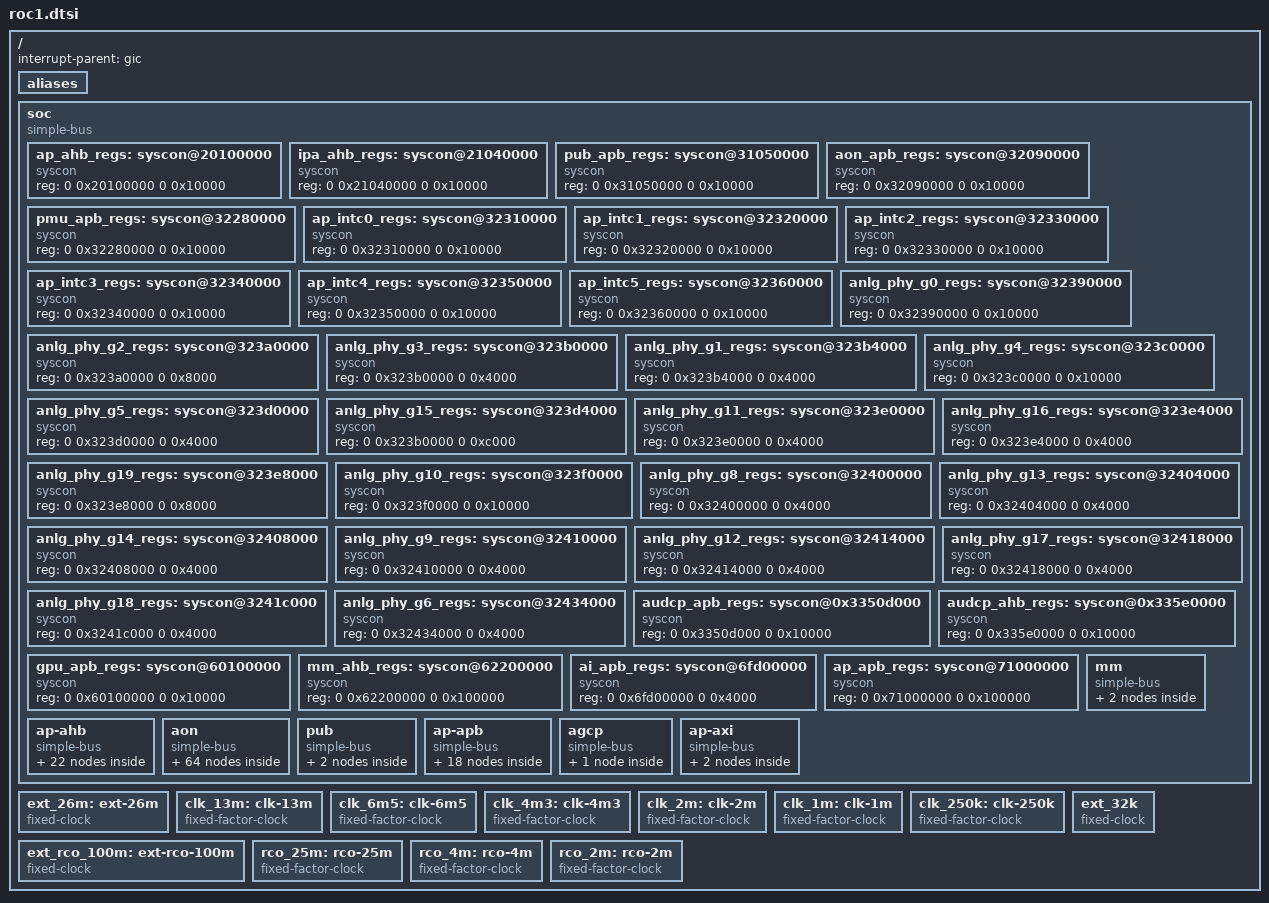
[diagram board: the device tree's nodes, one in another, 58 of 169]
/*
 * Spreadtrum Roc1 platform DTS file
 *
 * Copyright (C) 2018, Spreadtrum Communications Inc.
 *
 * This file is licensed under a dual GPLv2 or X11 license.
 */

#include <dt-bindings/soc/sprd,roc1-regs.h>
#include <dt-bindings/soc/sprd,roc1-mask.h>
#include <dt-bindings/clock/sprd,roc1-clk.h>
#include <dt-bindings/interrupt-controller/arm-gic.h>
#include <dt-bindings/debug/busmonitor/busmonitor.h>
#include <dt-bindings/debug/dmc_mpu/roc1_dmc_mpu.h>

/ {
	interrupt-parent = <&gic>;
	#address-cells = <2>;
	#size-cells = <2>;

	aliases {
		i2c0 = &i2c0;
		i2c1 = &i2c1;
		i2c2 = &i2c2;
		i2c3 = &i2c3;
		i2c4 = &i2c4;
		i2c5 = &i2c5;
		i2c6 = &i2c6;
		spi0 = &spi0;
		spi1 = &spi1;
		spi2 = &spi2;
		spi3 = &spi3;
	};

	soc: soc {
		compatible = "simple-bus";
		#address-cells = <2>;
		#size-cells = <2>;
		ranges;

		ap_ahb_regs: syscon@20100000 {
			compatible = "syscon";
			#syscon-cells = <2>;
			reg = <0 0x20100000 0 0x10000>;
		};

		ipa_ahb_regs: syscon@21040000 {
			compatible = "syscon";
			#syscon-cells = <2>;
			reg = <0 0x21040000 0 0x10000>;
		};

		pub_apb_regs: syscon@31050000 {
			compatible = "syscon";
			#syscon-cells = <2>;
			reg = <0 0x31050000 0 0x10000>;
		};

		aon_apb_regs: syscon@32090000 {
			compatible = "syscon";
			#syscon-cells = <2>;
			reg = <0 0x32090000 0 0x10000>;
		};

		pmu_apb_regs: syscon@32280000 {
			compatible = "syscon";
			#syscon-cells = <2>;
			reg = <0 0x32280000 0 0x10000>;
		};

		ap_intc0_regs: syscon@32310000 {
			compatible = "syscon";
			#syscon-cells = <2>;
			reg = <0 0x32310000 0 0x10000>;
		};

		ap_intc1_regs: syscon@32320000 {
			compatible = "syscon";
			#syscon-cells = <2>;
			reg = <0 0x32320000 0 0x10000>;
		};

		ap_intc2_regs: syscon@32330000 {
			compatible = "syscon";
			#syscon-cells = <2>;
			reg = <0 0x32330000 0 0x10000>;
		};

		ap_intc3_regs: syscon@32340000 {
			compatible = "syscon";
			#syscon-cells = <2>;
			reg = <0 0x32340000 0 0x10000>;
		};

		ap_intc4_regs: syscon@32350000 {
			compatible = "syscon";
			#syscon-cells = <2>;
			reg = <0 0x32350000 0 0x10000>;
		};

		ap_intc5_regs: syscon@32360000 {
			compatible = "syscon";
			#syscon-cells = <2>;
			reg = <0 0x32360000 0 0x10000>;
		};

		anlg_phy_g0_regs: syscon@32390000 {
			compatible = "syscon";
			#syscon-cells = <2>;
			reg = <0 0x32390000 0 0x10000>;
		};

		anlg_phy_g2_regs: syscon@323a0000 {
			compatible = "syscon";
			#syscon-cells = <2>;
			reg = <0 0x323a0000 0 0x8000>;
		};

		anlg_phy_g3_regs: syscon@323b0000 {
			compatible = "syscon";
			#syscon-cells = <2>;
			reg = <0 0x323b0000 0 0x4000>;
		};

		anlg_phy_g1_regs: syscon@323b4000 {
			compatible = "syscon";
			#syscon-cells = <2>;
			reg = <0 0x323b4000 0 0x4000>;
		};

		anlg_phy_g4_regs: syscon@323c0000 {
			compatible = "syscon";
			#syscon-cells = <2>;
			reg = <0 0x323c0000 0 0x10000>;
		};

		anlg_phy_g5_regs: syscon@323d0000 {
			compatible = "syscon";
			#syscon-cells = <2>;
			reg = <0 0x323d0000 0 0x4000>;
		};

		anlg_phy_g15_regs: syscon@323d4000 {
			compatible = "syscon";
			#syscon-cells = <2>;
			reg = <0 0x323b0000 0 0xc000>;
		};

		anlg_phy_g11_regs: syscon@323e0000 {
			compatible = "syscon";
			#syscon-cells = <2>;
			reg = <0 0x323e0000 0 0x4000>;
		};

		anlg_phy_g16_regs: syscon@323e4000 {
			compatible = "syscon";
			#syscon-cells = <2>;
			reg = <0 0x323e4000 0 0x4000>;
		};

		anlg_phy_g19_regs: syscon@323e8000 {
			compatible = "syscon";
			#syscon-cells = <2>;
			reg = <0 0x323e8000 0 0x8000>;
		};

		anlg_phy_g10_regs: syscon@323f0000 {
			compatible = "syscon";
			#syscon-cells = <2>;
			reg = <0 0x323f0000 0 0x10000>;
		};

		anlg_phy_g8_regs: syscon@32400000 {
			compatible = "syscon";
			#syscon-cells = <2>;
			reg = <0 0x32400000 0 0x4000>;
		};

		anlg_phy_g13_regs: syscon@32404000 {
			compatible = "syscon";
			#syscon-cells = <2>;
			reg = <0 0x32404000 0 0x4000>;
		};

		anlg_phy_g14_regs: syscon@32408000 {
			compatible = "syscon";
			#syscon-cells = <2>;
			reg = <0 0x32408000 0 0x4000>;
		};

		anlg_phy_g9_regs: syscon@32410000 {
			compatible = "syscon";
			#syscon-cells = <2>;
			reg = <0 0x32410000 0 0x4000>;
		};

		anlg_phy_g12_regs: syscon@32414000 {
			compatible = "syscon";
			#syscon-cells = <2>;
			reg = <0 0x32414000 0 0x4000>;
		};

		anlg_phy_g17_regs: syscon@32418000 {
			compatible = "syscon";
			#syscon-cells = <2>;
			reg = <0 0x32418000 0 0x4000>;
		};

		anlg_phy_g18_regs: syscon@3241c000 {
			compatible = "syscon";
			#syscon-cells = <2>;
			reg = <0 0x3241c000 0 0x4000>;
		};

		anlg_phy_g6_regs: syscon@32434000 {
			compatible = "syscon";
			#syscon-cells = <2>;
			reg = <0 0x32434000 0 0x4000>;
		};

		audcp_apb_regs: syscon@0x3350d000 {
			compatible = "syscon";
			#syscon-cells = <2>;
			reg = <0 0x3350d000 0 0x10000>;
		};

		audcp_ahb_regs: syscon@0x335e0000 {
			compatible = "syscon";
			#syscon-cells = <2>;
			reg = <0 0x335e0000 0 0x10000>;
		};

		gpu_apb_regs: syscon@60100000 {
			compatible = "syscon";
			#syscon-cells = <2>;
			reg = <0 0x60100000 0 0x10000>;
		};

		mm_ahb_regs: syscon@62200000 {
			compatible = "syscon";
			#syscon-cells = <2>;
			reg = <0 0x62200000 0 0x100000>;
		};

		ai_apb_regs: syscon@6fd00000 {
			compatible = "syscon";
			#syscon-cells = <2>;
			reg = <0 0x6fd00000 0 0x4000>;
		};

		ap_apb_regs: syscon@71000000 {
			compatible = "syscon";
			#syscon-cells = <2>;
			reg = <0 0x71000000 0 0x100000>;
		};

		mm {
			compatible = "simple-bus";
			#address-cells = <2>;
			#size-cells = <2>;
			ranges;

			gpu: gpu@60000000 {
				compatible = "sprd,rogue";
				reg = <0x0 0x60000000 0x0 0x100000>;
				interrupts = <GIC_SPI 60 IRQ_TYPE_LEVEL_HIGH>;
			};

			jpg: jpg-codec@62700000{
				compatible = "sprd,roc1-jpg";
				reg = <0 0x62700000 0 0xc000>;
				interrupts = <GIC_SPI 42 IRQ_TYPE_LEVEL_HIGH>;

				syscons = <&mm_ahb_regs REG_MM_AHB_AHB_RST
						MASK_MM_AHB_JPG_SOFT_RST>,
					<&aon_apb_regs
						REG_AON_APB_APB_EB0
						MASK_AON_APB_MM_EB>;
				syscon-names = "reset",
					"aon_apb_eb";
				status = "disabled";
			};
		};

		ap-ahb {
			compatible = "simple-bus";
			#address-cells = <2>;
			#size-cells = <2>;
			ranges;

			ap_dma: dma-controller@20000000 {
				compatible = "sprd,roc1-dma";
				reg = <0 0x20000000 0 0x4000>;
				interrupts = <GIC_SPI 24 IRQ_TYPE_LEVEL_HIGH>;
				#dma-cells = <1>;
				#dma-channels = <28>;
				clock-names = "enable";
				clocks = <&apahb_gate CLK_DMA_PUB_EB>;
			};

			hsphy: hsphy@20100000 {
				compatible = "sprd,roc1-phy";
				sprd,syscon-enable = <&aon_apb_regs>;
				sprd,syscon-anag3 = <&anlg_phy_g3_regs>;
				sprd,vdd-voltage = <3300000>;
				#phy-cells = <0>;
			};

			dpu: dpu@20300000 {
				compatible = "sprd,display-processor";
				reg = <0 0x20300000 0 0x1000>;
				interrupts = <GIC_SPI 27 IRQ_TYPE_LEVEL_HIGH>;
				status = "disabled";

				dma-coherent;

				sprd,ip = "dpu-r3p0";
				/* sprd,soc = "roc1"; */

				//sprd,syscon-aon-apb = <&aon_apb_controller>;

				dpu_port: port {
					dpu_out: endpoint {
						remote-endpoint = <&dsi_in>;
					};
				};
			};

			gsp_core0: gsp@20300000 {
				compatible = "sprd,gsp-core";
				reg = <0 0x20300000 0 0x2000>;
				core-id = <0>;
				kcfg-num = <16>;
				interrupts = <GIC_SPI 26 IRQ_TYPE_LEVEL_HIGH>;
				iommus = <&iommu_dispc>;
			};

			iommu_dispc: iommu@20300000 {
				compatible = "sprd,iommuexroc1-dispc";
				reg = <0 0x20300000 0 0x800>,
				      <0 0x20300800 0 0x80>;
				iova-base = <0x30000000>;
				iova-size = <0x10000000>;
				reg_name = "mmu_interrupt_reg","mmu_reg";
				status = "disabled";
				#iommu-cells = <0>;
			};

			iommu_ai: iommu@6fe00000 {
				compatible = "sprd,iommuexroc1-ai";
				reg = <0 0x6fe00000 0 0x800>,
				      <0 0x6fd08004 0 0x80>;
				iova-base = <0x30000000>;
				iova-size = <0x20000000>;
				reg_name = "mmu_interrupt_reg","mmu_reg";
				status = "disabled";
				#iommu-cells = <0>;
			};

			dsi: dsi@20400000 {
				compatible = "sprd,dsi-host";
				reg = <0 0x20400000 0 0x1000>;
				interrupts = <GIC_SPI 30 IRQ_TYPE_LEVEL_HIGH>,
					<GIC_SPI 31 IRQ_TYPE_LEVEL_HIGH>;
				status = "disabled";

				sprd,ip = "sprd,dsi-ctrl", "r3p0";
				sprd,soc = "roc1";

				//sprd,syscon-aon-apb = <&aon_apb_controller>;

				ports {
					#address-cells = <1>;
					#size-cells = <0>;

					port@0 {
						reg = <0>;
						dsi_out: endpoint {
							remote-endpoint = <&dphy_in>;
						};
					};

					port@1 {
						reg = <1>;
						dsi_in: endpoint@1 {
							remote-endpoint = <&dpu_out>;
						};
					};
				};
			};

			dphy: dphy {
				compatible = "sprd,dsi-phy";
				#address-cells = <1>;
				#size-cells = <0>;
				reg = <0 0x20400000 0 0x1000>;
				status = "disabled";

				sprd,ip = "sprd,megacores-sharkl5";
				sprd,soc = "roc1";

				//sprd,syscon-aon-apb = <&aon_apb_controller>;

				/* output port */
				port@0 {
					reg = <0>;
					dphy_out: endpoint {
						remote-endpoint = <&panel_in>;
					};
				};

				/* input port*/
				port@1 {
					reg = <1>;
					dphy_in: endpoint {
						remote-endpoint = <&dsi_out>;
					};
				};
			};

			vsp: video-codec@20500000{
				compatible = "sprd,roc1-vsp";
				reg = <0 0x20500000 0 0xc000>;
				interrupts = <GIC_SPI 34 IRQ_TYPE_LEVEL_HIGH>;
				syscons = <&ap_ahb_regs REG_AP_AHB_AHB_RST
					(MASK_AP_AHB_VSP_SOFT_RST |
					MASK_AP_AHB_VSP_GLOBAL_SOFT_RST)>,
					<&pmu_apb_regs
					REG_PMU_APB_PD_AP_VSP_CFG
					MASK_PMU_APB_PD_AP_VSP_FORCE_SHUTDOWN>,
					<&pmu_apb_regs
					REG_PMU_APB_PD_AP_VSP_CFG
					MASK_PMU_APB_PD_AP_VSP_AUTO_SHUTDOWN_EN>
					,
					<&pmu_apb_regs
					REG_PMU_APB_PWR_STATUS0_DBG
					MASK_PMU_APB_PD_AP_VSP_STATE>,
					<&aon_apb_regs
					REG_AON_APB_APB_EB1
					MASK_AON_APB_AP_SYST_EB>;
				syscon-names = "reset",
					"pmu_vsp_force_shutdown",
					"pmu_vsp_auto_shutdown",
					"pmu_pwr_status",
					"vsp_domain_eb";
				status = "disabled";
			};

			pcie0: pcie@20c00000 {
				compatible = "sprd,pcie", "snps,dw-pcie";
				reg = <0x0 0x20c00000 0x0 0x100000>,
				      <0x3 0xffffe000 0x0 0x2000>;
				reg-names = "dbi", "config";
				#address-cells = <3>;
				#size-cells = <2>;
				device_type = "pci";
				ranges = <0x01000000 0x0 0x00000000 0x3 0xfffee000 0x0 0x00010000
					  0x03000000 0x0 0x10000000 0x3 0xf8000000 0x0 0x07fee000>;
				interrupts = <GIC_SPI 148 IRQ_TYPE_LEVEL_HIGH>;
				bus-range = <0 15>;
				num-lanes = <1>;
				num-vectors = <256>;
				num-viewport = <8>;
				status = "okay";
			};

			pcie1: pcie@20d00000 {
				compatible = "sprd,pcie", "snps,dw-pcie";
				reg = <0x0 0x20d00000 0x0 0x100000>,
				      <0x3 0xf7f00000 0x0 0x100000>;
				reg-names = "dbi", "config";
				#address-cells = <3>;
				#size-cells = <2>;
				device_type = "pci";
				ranges = <0x01000000 0x0 0x00000000 0x3 0xf7ef0000 0x0 0x00010000
					  0x03000000 0x0 0x10000000 0x2 0x80000000 0x1 0x77ef0000>;
				interrupts = <GIC_SPI 153 IRQ_TYPE_LEVEL_HIGH>;
				bus-range = <16 31>;
				num-lanes = <1>;
				num-vectors = <256>;
				num-viewport = <8>;
				status = "okay";
			};
		};

		aon {
			compatible = "simple-bus";
			#address-cells = <2>;
			#size-cells = <2>;
			ranges;

			eic_debounce: gpio@32000000 {
				compatible = "sprd,roc1-eic-debounce";
				reg = <0 0x32020000 0 0x80>,
				      <0 0x32030000 0 0x80>,
				      <0 0x32230000 0 0x80>,
				      <0 0x32270000 0 0x80>;
				gpio-controller;
				#gpio-cells = <2>;
				interrupt-controller;
				#interrupt-cells = <2>;
				interrupts = <GIC_SPI 72 IRQ_TYPE_LEVEL_HIGH>;
			};

			eic_latch: gpio@32000080 {
				compatible = "sprd,roc1-eic-latch";
				reg = <0 0x32020080 0 0x20>,
				      <0 0x32030080 0 0x20>,
				      <0 0x32230080 0 0x20>,
				      <0 0x32270080 0 0x20>;
				gpio-controller;
				#gpio-cells = <2>;
				interrupt-controller;
				#interrupt-cells = <2>;
				interrupts = <GIC_SPI 72 IRQ_TYPE_LEVEL_HIGH>;
			};

			eic_async: gpio@320000a0 {
				compatible = "sprd,roc1-eic-async";
				reg = <0 0x320200a0 0 0x20>,
				      <0 0x320300a0 0 0x20>,
				      <0 0x322300a0 0 0x20>,
				      <0 0x322700a0 0 0x20>;
				gpio-controller;
				#gpio-cells = <2>;
				interrupt-controller;
				#interrupt-cells = <2>;
				interrupts = <GIC_SPI 72 IRQ_TYPE_LEVEL_HIGH>;
			};

			eic_sync: gpio@320000c0 {
				compatible = "sprd,roc1-eic-sync";
				reg = <0 0x320200c0 0 0x20>,
				      <0 0x320300c0 0 0x20>,
				      <0 0x322300c0 0 0x20>,
				      <0 0x322700c0 0 0x20>;
				gpio-controller;
				#gpio-cells = <2>;
				interrupt-controller;
				#interrupt-cells = <2>;
				interrupts = <GIC_SPI 72 IRQ_TYPE_LEVEL_HIGH>;
			};

			timer@32050000 {
				compatible = "sprd,roc1-timer";
				reg = <0 0x32050000 0 0x20>;
				interrupts = <GIC_SPI 71 IRQ_TYPE_LEVEL_HIGH>;
				clocks = <&ext_32k>;
			};

			timer@32050020 {
				compatible = "sprd,roc1-suspend-timer";
				reg = <0 0x32050020 0 0x20>;
				clocks = <&ext_32k>;
			};

			i2c5: i2c@32060000 {
				compatible = "sprd,roc1-hw-i2c";
				reg = <0 0x32060000 0 0x1000>;
				interrupts = <GIC_SPI 68 IRQ_TYPE_LEVEL_HIGH>;
				clock-names = "source", "enable", "i2c",
						"clk_hw_i2c";
				clock-frequency = <400000>;
				#address-cells = <1>;
				#size-cells = <0>;
				status = "disabled";
			};

			ap_gpio: gpio@32070000 {
				compatible = "sprd,roc1-gpio";
				reg = <0 0x32070000 0 0x10000>;
				gpio-controller;
				#gpio-cells = <2>;
				interrupt-controller;
				#interrupt-cells = <2>;
				interrupts = <GIC_SPI 61 IRQ_TYPE_LEVEL_HIGH>;
			};

			ap_thm0: thermal@32200000 {
				compatible = "sprd,roc1-thermal";
				reg = <0 0x32200000 0 0x10000>;
				clock-names = "enable";
				clocks = <&aonapb_gate CLK_THM0_EB>;
				#thermal-sensor-cells = <1>;
				nvmem-cells = <&thm0_sign>, <&thm0_ratio>;
				nvmem-cell-names = "thm_sign_cal", "thm_ratio_cal";

				core6a7-big@0{
					reg = <0>;
					nvmem-cells = <&thm0_sen0>;
					nvmem-cell-names = "sen_delta_cal";
				};

				core4-big@1{
					reg = <1>;
					nvmem-cells = <&thm0_sen1>;
					nvmem-cell-names = "sen_delta_cal";
				};

				core5-big@2{
					reg = <2>;
					nvmem-cells = <&thm0_sen2>;
					nvmem-cell-names = "sen_delta_cal";
				};

				core6-big@3{
					reg = <3>;
					nvmem-cells = <&thm0_sen3>;
					nvmem-cell-names = "sen_delta_cal";
				};

				core7-big@4{
					reg = <4>;
					nvmem-cells = <&thm0_sen4>;
					nvmem-cell-names = "sen_delta_cal";
				};
			};

			ap_thm1: thermal@32210000 {
				compatible = "sprd,roc1-thermal";
				reg = <0 0x32210000 0 0x10000>;
				clock-names = "enable";
				clocks = <&aonapb_gate CLK_THM1_EB>;
				#thermal-sensor-cells = <1>;
				nvmem-cells = <&thm1_sign>, <&thm1_ratio>;
				nvmem-cell-names = "thm_sign_cal", "thm_ratio_cal";

				ai0-sensor@0{
					reg = <0>;
					nvmem-cells = <&thm1_sen0>;
					nvmem-cell-names = "sen_delta_cal";
				};

				ai1-sensor@1{
					reg = <1>;
					nvmem-cells = <&thm1_sen1>;
					nvmem-cell-names = "sen_delta_cal";
				};
			};

			ap_thm2: thermal@32220000 {
				compatible = "sprd,roc1-thermal";
				reg = <0 0x32220000 0 0x10000>;
				clock-names = "enable";
				clocks = <&aonapb_gate CLK_THM2_EB>;
				#thermal-sensor-cells = <1>;
				nvmem-cells = <&thm2_sign>, <&thm2_ratio>;
				nvmem-cell-names = "thm_sign_cal", "thm_ratio_cal";

				gpu0-sensor@0{
					reg = <0>;
					nvmem-cells = <&thm2_sen0>;
					nvmem-cell-names = "sen_delta_cal";
				};

				mm-sensor@1{
					reg = <1>;
					nvmem-cells = <&thm2_sen1>;
					nvmem-cell-names = "sen_delta_cal";
				};
			};

			ap_thm3: thermal@32520000 {
				compatible = "sprd,roc1-thermal";
				reg = <0 0x32520000 0 0x10000>;
				clock-names = "enable";
				clocks = <&aonapb_gate CLK_THM3_EB>;
				#thermal-sensor-cells = <1>;
				nvmem-cells = <&thm3_sign>, <&thm3_ratio>;
				nvmem-cell-names = "thm_sign_cal", "thm_ratio_cal";

				cputop0-sensor@0{
					reg = <0>;
					nvmem-cells = <&thm3_sen0>;
					nvmem-cell-names = "sen_delta_cal";
				};

				core0-little@1{
					reg = <1>;
					nvmem-cells = <&thm3_sen1>;
					nvmem-cell-names = "sen_delta_cal";
				};

				core1-little@2{
					reg = <2>;
					nvmem-cells = <&thm3_sen2>;
					nvmem-cell-names = "sen_delta_cal";
				};

				core2-little@3{
					reg = <3>;
					nvmem-cells = <&thm3_sen3>;
					nvmem-cell-names = "sen_delta_cal";
				};

				core3-little@4{
					reg = <4>;
					nvmem-cells = <&thm3_sen4>;
					nvmem-cell-names = "sen_delta_cal";
				};

				cputop1-sensor@5{
					reg = <5>;
					nvmem-cells = <&thm3_sen5>;
					nvmem-cell-names = "sen_delta_cal";
				};

				gpu1-sensor@6{
					reg = <6>;
					nvmem-cells = <&thm3_sen6>;
					nvmem-cell-names = "sen_delta_cal";
				};
			};

			ap_efuse: efuse@32240000 {
				compatible = "sprd,roc1-efuse";
				reg = <0 0x32240000 0 0x10000>;
				clock-names = "enable";
				hwlocks = <&hwlock 8>;
				clocks = <&aonapb_gate CLK_EFUSE_EB>;

				thm0_sign: thm0-sign@8c{
					reg = <0x8c 0x4>;
					bits = <0 1>;
				};

				thm0_ratio: thm0-ratio@8c{
					reg = <0x8c 0x4>;
					bits = <1 7>;
				};

				thm0_sen0: thm0-sen0@8c{
					reg = <0x8c 0x4>;
					bits = <8 8>;
				};

				thm0_sen1: thm0-sen1@94{
					reg = <0x94 0x4>;
					bits = <8 8>;
				};

				thm0_sen2: thm0-sen2@94{
					reg = <0x94 0x4>;
					bits = <0 8>;
				};

				thm0_sen3: thm0-sen3@94{
					reg = <0x94 0x4>;
					bits = <24 8>;
				};

				thm0_sen4: thm0-sen4@94{
					reg = <0x94 0x4>;
					bits = <16 8>;
				};

				thm1_sign: thm1-sign@90{
					reg = <0x90 0x4>;
					bits = <0 1>;
				};

				thm1_ratio: thm1-ratio@90{
					reg = <0x90 0x4>;
					bits = <1 7>;
				};

				thm1_sen0: thm1-sen0@90{
					reg = <0x90 0x4>;
					bits = <8 8>;
				};

				thm1_sen1: thm1-sen1@98{
					reg = <0x98 0x4>;
					bits = <8 8>;
				};

				thm2_sign: thm2-sign@90{
					reg = <0x90 0x4>;
					bits = <16 1>;
				};

				thm2_ratio: thm2-ratio@90{
					reg = <0x90 0x4>;
					bits = <17 7>;
				};

				thm2_sen0: thm2-sen0@90{
					reg = <0x90 0x4>;
					bits = <24 8>;
				};

				thm2_sen1: thm2-sen0@98{
					reg = <0x98 0x4>;
					bits = <0 8>;
				};

				thm3_sign: thm3-sign@6c{
					reg = <0x6c 0x4>;
					bits = <0 1>;
				};

				thm3_ratio: thm3-ratio@6c{
					reg = <0x6c 0x4>;
					bits = <1 7>;
				};

				thm3_sen0: thm3-sen0@6c{
					reg = <0x6c 0x4>;
					bits = <8 8>;
				};

				thm3_sen1: thm3-sen1@98{
					reg = <0x98 0x4>;
					bits = <24 8>;
				};

				thm3_sen2: thm3-sen2@98{
					reg = <0x98 0x4>;
					bits = <16 8>;
				};

				thm3_sen3: thm3-sen3@68{
					reg = <0x68 0x4>;
					bits = <8 8>;
				};

				thm3_sen4: thm3-sen4@68{
					reg = <0x68 0x4>;
					bits = <0 8>;
				};

				thm3_sen5: thm3-sen5@68{
					reg = <0x68 0x4>;
					bits = <24 8>;
				};

				thm3_sen6: thm3-sen6@68{
					reg = <0x68 0x4>;
					bits = <16 8>;
				};
			};

			pwms: pwm@32260000 {
				compatible = "sprd,sharkl5-pwm", "sprd,roc1-pwm";
				reg = <0 0x32260000 0 0x10000>;
				status = "disabled";
				clock-names = "clk_parent",
					"clk_pwm0", "clk_pwm0_eb",
					"clk_pwm1", "clk_pwm1_eb",
					"clk_pwm2", "clk_pwm2_eb",
					"clk_pwm3", "clk_pwm3_eb";
				clocks = <&ext_26m>,
					<&aon_clk CLK_AON_PWM0>,
					<&aonapb_gate CLK_PWM0_EB>,
					<&aon_clk CLK_AON_PWM1>,
					<&aonapb_gate CLK_PWM1_EB>,
					<&aon_clk CLK_AON_PWM2>,
					<&aonapb_gate CLK_PWM2_EB>,
					<&aon_clk CLK_AON_PWM3>,
					<&aonapb_gate CLK_PWM3_EB>;
				#pwm-cells = <2>;
			};

			usb: usb@0x5fff0000 {
				compatible = "sprd,roc1-musb";
				reg = <0 0x5fff0000 0 0x2000>;
				interrupts = <GIC_SPI 69 IRQ_TYPE_LEVEL_HIGH>;
				interrupt-names = "mc";
				clocks = <&aonapb_gate CLK_OTG_UTMI_EB>;
				clock-names = "core_clk";
				usb-phy = <&hsphy>;
				phy-names = "usb";
				dr-mode = "peripheral";
			};

			aon_mailbox: mailbox@320a0000 {
				compatible = "sprd,mailbox";
				reg = <0 0x320a0000 0 0x8000>,
				      <0 0x320a8000 0 0x8000>;
				syscons = <&aon_apb_regs 0x4 0x4>;
				syscon-names = "clk";
				interrupts = <GIC_SPI 82 IRQ_TYPE_LEVEL_HIGH>,
					     <GIC_SPI 83 IRQ_TYPE_LEVEL_HIGH>,
					     <GIC_SPI 84 IRQ_TYPE_LEVEL_HIGH>;
				sprd,sensor = <6>;
				sprd,core-cnt = <7>;
				sprd,version = <3>;
			};

			adi_bus: spi@32100000 {
				compatible = "sprd,sharkl5-adi", "sprd,roc1-adi";
				reg = <0 0x32100000 0 0x100000>;
				#address-cells = <1>;
				#size-cells = <0>;
			};

			watchdog@322f0000 {
				compatible = "sprd,sharkl5-wdt";
				reg = <0 0x322f0000 0 0x10000>;
				interrupts = <GIC_SPI 79 IRQ_TYPE_LEVEL_HIGH>;
				timeout-sec = <12>;
				clock-names = "enable", "rtc_enable";
				clocks = <&aonapb_gate CLK_APCPU_WDG_EB>,
					<&aonapb_gate CLK_AP_WDG_RTC_EB>;
			};

			i2c6: i2c@32370000 {
				compatible = "sprd,roc1-hw-i2c";
				reg = <0 0x32370000 0 0x1000>;
				interrupts = <GIC_SPI 131 IRQ_TYPE_LEVEL_HIGH>;
				clock-names = "source", "enable", "i2c",
						"clk_hw_i2c";
				clock-frequency = <400000>;
				#address-cells = <1>;
				#size-cells = <0>;
				status = "disabled";
			};

			pin_controller: pinctrl@3243c000 {
				compatible = "sprd,roc1-pinctrl";
				reg = <0 0x3243c000 0 0x20000>;
			};

			djtag: djtag@324e0000 {
				compatible = "sprd,djtag";
				reg = <0 0x324e0000 0 0x1000>;
				syscon-names = "soft_rst";
				syscons = <&aon_apb_regs REG_AON_APB_APB_RST3
					MASK_AON_APB_DJTAG_SOFT_RST>;
				clock-names = "enable", "tck";
				clocks = <&aonapb_gate CLK_DJTAG_EB>,
					<&aonapb_gate CLK_DJTAG_TCK_EB>;
				hwlocks = <&hwlock 10>;
				hwlock-names = "djtag";

				#address-cells = <1>;
				#size-cells = <0>;

				aon-busmonitor@8{
					compatible  = "sprd,roc1-busmonitor";
					interrupts = <GIC_SPI 81
						IRQ_TYPE_LEVEL_HIGH>;
					reg = <0x8>;
					sprd,bm-num = <6>;
					sprd,bm-name =
						"AP", "WTLCP", "AUDCP", "PUBCP",
						"USBOTG", "CM4";
					sprd,bm-type =
						<AXI>, <AXI>, <AXI>,
						<AXI>, <AXI>, <AXI>;
					sprd,bm-dap = <0>, <1>, <2>, <3>,
						<4>, <5>;
					sprd,bm-config =
						<ENABLE MON_WRITE MON_INSIDE>,
						<ENABLE MON_WRITE MON_INSIDE>,
						<ENABLE MON_WRITE MON_INSIDE>,
						<ENABLE MON_WRITE MON_INSIDE>,
						<DISABLE MON_WRITE MON_INSIDE>,
						<ENABLE MON_WRITE MON_INSIDE>;
					sprd,bm-id =
						<DISABLE 0 AXIID>,
						<DISABLE 0 AXIID>,
						<DISABLE 0 AXIID>,
						<DISABLE 0 AXIID>,
						<DISABLE 0 AXIID>,
						<DISABLE 0 AXIID>;
					sprd,bm-ranges =
						<0x5ffe0000 0x5ffe0018>,
						<0x5ffe0000 0x5ffe0018>,
						<0x5ffe0000 0x5ffe0018>,
						<0x0ffe0000 0x0ffe0018>,
						<0 0>,
						<0x5ffe0000 0x5ffe0018>;
				};
			};

			hwlock: hwspinlock@32500000 {
				compatible = "sprd,roc1-hwspinlock";
				reg = <0 0x32500000 0 0x10000>;
				#hwlock-cells = <1>;
				clock-names = "enable";
				clocks = <&aonapb_gate CLK_SPLK_EB>;
			};

			apb_bm: apb-busmonitor@32540000 {
				compatible = "sprd,roc1-apb-busmonitor";
				reg = <0 0x32540000 0 0x1000>;
				interrupts = <GIC_SPI 102 IRQ_TYPE_LEVEL_HIGH>;
				sprd,target-addr = <0 0>;
				sprd,target-data = <0 0>;
			};
		};

		pub {
			compatible = "simple-bus";
			#address-cells = <2>;
			#size-cells = <2>;
			ranges;

			dmc_mpu: dmc-mpu@31030000 {
				compatible = "sprd,roc1-dmc-mpu";
				reg = <0 0x31030000 0 0x10000>;
				interrupts = <GIC_SPI 111 IRQ_TYPE_LEVEL_HIGH>;
				syscon-names = "irq_clr", "irq_en";
				syscons = <&pub_apb_regs
					REG_PUB_APB_PUB_INT_CTRL
					MASK_PUB_APB_DMC_MPU_VIO_INT_CLR>,
					<&pub_apb_regs
					REG_PUB_APB_PUB_INT_CTRL
					MASK_PUB_APB_DMC_MPU_VIO_INT_EN>;
				sprd,channel-num = <8>;
				sprd,mpu-num = <16>;
				sprd,channel-names =
					"CPU", "GPU", "DPU/DCAM","ISP/VDSP",
					"AP/VSP/AON/eSE/IPA-1", "WTLCP",
					"PUBCP/AUDCP/IPA-2","AI",
					"SHARED0", "SHARED1", "SHARED2",
					"SHARED3", "SHARED4", "SHARED5",
					"SHARED6", "SHARED7";
				sprd,ranges = <0 0 0 0>, <0 0 0 0>, <0 0 0 0>,
					<0 0 0 0>, <0 0 0 0>, <0 0 0 0>,
					<0 0 0 0>, <0 0 0 0>, <0 0 0 0>,
					<0 0 0 0>, <0 0 0 0>, <0 0 0 0>,
					<0 0 0 0>, <0 0 0 0>, <0 0 0 0>,
					<0 0 0 0>;
				sprd,chn-config =
					<DISABLE MON_INSIDE MON_WRITE>,
					<DISABLE MON_INSIDE MON_WRITE>,
					<DISABLE MON_INSIDE MON_WRITE>,
					<DISABLE MON_INSIDE MON_WRITE>,
					<DISABLE MON_INSIDE MON_WRITE>,
					<DISABLE MON_INSIDE MON_WRITE>,
					<DISABLE MON_INSIDE MON_WRITE>,
					<DISABLE MON_INSIDE MON_WRITE>,
					<DISABLE MON_INSIDE MON_WRITE>,
					<DISABLE MON_INSIDE MON_WRITE>,
					<DISABLE MON_INSIDE MON_WRITE>,
					<DISABLE MON_INSIDE MON_WRITE>,
					<DISABLE MON_INSIDE MON_WRITE>,
					<DISABLE MON_INSIDE MON_WRITE>,
					<DISABLE MON_INSIDE MON_WRITE>,
					<DISABLE MON_INSIDE MON_WRITE>;
				sprd,id-config =
					<MPUID 0 0xffff>, <MPUID 0 0xffff>,
					<MPUID 0 0xffff>, <MPUID 0 0xffff>,
					<MPUID 0 0xffff>, <MPUID 0 0xffff>,
					<MPUID 0 0xffff>, <MPUID 0 0xffff>,
					<MPUID 0 0xffff>, <MPUID 0 0xffff>,
					<MPUID 0 0xffff>, <MPUID 0 0xffff>,
					<MPUID 0 0xffff>, <MPUID 0 0xffff>,
					<MPUID 0 0xffff>, <MPUID 0 0xffff>;
				sprd,port-map = <0>, <1>, <2>, <3>, <4>,
						<5>, <6>, <7>, <0>, <0>,
						<0>, <0>, <0>, <0>, <0>,
						<0>;
				sprd,ddr-offset = <0x80000000>;
				status = "disabled";
			};

			ptm_trace: ptm@31060000 {
				compatible = "sprd,roc1-ptm";
				reg = <0x0 0x31060000 0x0 0x10000>,
					<0x0 0x3c002000 0x0 0x1000>,
					<0x0 0x3c003000 0x0 0x1000>,
					<0x0 0x3c006000 0x0 0x1000>;
				interrupts = <GIC_SPI 109 IRQ_TYPE_LEVEL_HIGH>;
				clock-names = "clk_cs","cs_src";
				clocks = <&aon_clk CLK_CSSYS>,
					<&g12_pll CLK_TWPLL_153M6>;
				sprd,funnel-port = <3>;
				sprd,ddr-chn = <8>;
				sprd,chn-name = "CPU", "GPU", "DPU/DCAM",
					"ISP/VDSP", "AP/VSP/AON/eSE/IPA1",
					"WTLCP","PUBCP/AUDCP/IPA2","AI";
			};
		};

		ap-apb {
			compatible = "simple-bus";
			#address-cells = <2>;
			#size-cells = <2>;
			ranges;

			pam_ipa: pam-ipa@21140000 {
				compatible = "sprd,pam-ipa";
				reg = <0 0x21140000 0 0x100>;
				reg-names = "pam-ipa-base";

				sprd,cp-ul-intr-to-ap = <0>;
				sprd,cp-ul-threshold = <1>;
				sprd,cp-ul-timeout = <5>;
				sprd,cp-ul-flowctrl-mode = <1>;
				sprd,cp-ul-enter-flowctrl-watermark = <0x10>;
				sprd,cp-ul-exit-flowctrl-watermark = <0x04>;
				sprd,cp-dl-intr-to-ap = <0>;
				sprd,cp-dl-threshold = <0x10>;
				sprd,cp-dl-timeout = <0>;
				sprd,cp-dl-flowctrl-mode = <0>;
				sprd,cp-dl-enter-flowctrl-watermark = <0x24>;
				sprd,cp-dl-exit-flowctrl-watermark = <0x04>;
				sprd,pam-ipa-hw-ver = <1>;
				sprd,pam-ipa-hw-mode = <0>;
			};

			ipa_local: ipa@21180000 {
				compatible = "sprd,sipa";
				reg = <0 0x21180000 0 0x00001000>,
					<0 0x21040000 0 0x00000140>,
					<0 0x20b10000 0 0x00040000>;
				reg-names = "glb-base", "ipa-sys", "iram-base";
				interrupts = <GIC_SPI 138 IRQ_TYPE_LEVEL_HIGH>;
				interrupt-names = "local_ipa_irq";

				sprd,sipa-bypass-mode = <0>;

				sprd,usb-dl-tx = <1 1024>;
				sprd,usb-dl-rx = <1 1024>;
				sprd,usb-ul-tx = <1 1024>;
				sprd,usb-ul-rx = <1 1024>;
				sprd,cp-dl-tx = <1 1024>;
				sprd,cp-dl-rx = <1 1024>;
				sprd,cp-ul-tx = <1 1024>;
				sprd,cp-ul-rx = <1 1024>;
				sprd,wifi-dl-tx = <1 1024>;
				sprd,wifi-dl-rx = <1 1024>;
				sprd,wifi-ul-tx = <1 1024>;
				sprd,wifi-ul-rx = <1 1024>;
				sprd,ap-eth-dl-tx = <0 1024>;
				sprd,ap-eth-dl-rx = <0 1024>;
				sprd,ap-eth-ul-tx = <0 1024>;
				sprd,ap-eth-ul-rx = <0 1024>;
				sprd,ap-ip-dl-tx = <0 1024>;
				sprd,ap-ip-dl-rx = <0 1024>;
				sprd,ap-ip-ul-tx = <0 1024>;
				sprd,ap-ip-ul-rx = <0 1024>;
				sprd,ap-pcie0-dl-tx = <0 256>;
				sprd,ap-pcie0-dl-rx = <0 256>;
				sprd,ap-pcie0-ul-tx = <0 256>;
				sprd,ap-pcie0-ul-rx = <0 256>;
				sprd,ap-pcie1-dl-tx = <0 256>;
				sprd,ap-pcie1-dl-rx = <0 256>;
				sprd,ap-pcie1-ul-tx = <0 256>;
				sprd,ap-pcie1-ul-rx = <0 256>;
				sprd,ap-pcie2-dl-tx = <0 0>;
				sprd,ap-pcie2-dl-rx = <0 0>;
				sprd,ap-pcie2-ul-tx = <0 0>;
				sprd,ap-pcie2-ul-rx = <0 0>;
				sprd,ap-pcie3-dl-tx = <0 0>;
				sprd,ap-pcie3-dl-rx = <0 0>;
				sprd,ap-pcie3-ul-tx = <0 0>;
				sprd,ap-pcie3-ul-rx = <0 0>;
			};

			uart0: serial@70000000 {
				compatible = "sprd,sc9836-uart";
				reg = <0 0x70000000 0 0x100>;
				interrupts = <GIC_SPI 2 IRQ_TYPE_LEVEL_HIGH>;
				clock-names = "enable", "uart", "source";
				clocks = <&apapb_gate CLK_UART0_EB>;
				status = "disabled";
			};

			uart1: serial@70100000 {
				compatible = "sprd,sc9836-uart";
				reg = <0 0x70100000 0 0x100>;
				interrupts = <GIC_SPI 3 IRQ_TYPE_LEVEL_HIGH>;
				clock-names = "enable", "uart", "source";
				clocks = <&apapb_gate CLK_UART1_EB>;
				status = "disabled";
			};

			uart2: serial@70200000 {
				compatible = "sprd,sc9836-uart";
				reg = <0 0x70200000 0 0x100>;
				interrupts = <GIC_SPI 4 IRQ_TYPE_LEVEL_HIGH>;
				clock-names = "enable", "uart", "source";
				clocks = <&apapb_gate CLK_UART2_EB>;
				status = "disabled";
			};

			i2c0: i2c@70300000 {
				compatible = "sprd,roc1-i2c";
				reg = <0 0x70300000 0 0x100>;
				interrupts = <GIC_SPI 11 IRQ_TYPE_LEVEL_HIGH>;
				clock-frequency = <400000>;
				#address-cells = <1>;
				#size-cells = <0>;
				status = "disabled";
			};

			i2c1: i2c@70400000 {
				compatible = "sprd,roc1-i2c";
				reg = <0 0x70400000 0 0x100>;
				interrupts = <GIC_SPI 12 IRQ_TYPE_LEVEL_HIGH>;
				clock-frequency = <400000>;
				#address-cells = <1>;
				#size-cells = <0>;
				status = "disabled";
			};

			i2c2: i2c@70500000 {
				compatible = "sprd,roc1-i2c";
				reg = <0 0x70500000 0 0x100>;
				interrupts = <GIC_SPI 13 IRQ_TYPE_LEVEL_HIGH>;
				clock-frequency = <400000>;
				#address-cells = <1>;
				#size-cells = <0>;
				status = "disabled";
			};

			i2c3: i2c@70600000 {
				compatible = "sprd,roc1-i2c";
				reg = <0 0x70600000 0 0x100>;
				interrupts = <GIC_SPI 14 IRQ_TYPE_LEVEL_HIGH>;
				clock-frequency = <400000>;
				#address-cells = <1>;
				#size-cells = <0>;
				status = "disabled";
			};

			i2c4: i2c@70700000 {
				compatible = "sprd,roc1-i2c";
				reg = <0 0x70700000 0 0x100>;
				interrupts = <GIC_SPI 15 IRQ_TYPE_LEVEL_HIGH>;
				clock-frequency = <400000>;
				#address-cells = <1>;
				#size-cells = <0>;
				status = "disabled";
			};

			spi0: spi@70800000{
				compatible = "sprd,sc9860-spi", "sprd,roc1-spi";
				reg = <0 0x70800000 0 0x1000>;
				interrupts = <GIC_SPI 5 IRQ_TYPE_LEVEL_HIGH>;
				clock-names = "enable", "spi", "source";
				clocks = <&apapb_gate CLK_SPI0_EB>;
				#address-cells = <1>;
				#size-cells = <0>;
				status = "disabled";
			};

			spi1: spi@70900000{
				compatible = "sprd,sc9860-spi", "sprd,roc1-spi";
				reg = <0 0x70900000 0 0x1000>;
				interrupts = <GIC_SPI 6 IRQ_TYPE_LEVEL_HIGH>;
				clock-names = "enable", "spi", "source";
				clocks = <&apapb_gate CLK_SPI1_EB>;
				#address-cells = <1>;
				#size-cells = <0>;
				status = "disabled";
			};

			spi2: spi@70a00000{
				compatible = "sprd,sc9860-spi", "sprd,roc1-spi";
				reg = <0 0x70a00000 0 0x1000>;
				interrupts = <GIC_SPI 7 IRQ_TYPE_LEVEL_HIGH>;
				clock-names = "enable", "spi", "source";
				clocks = <&apapb_gate CLK_SPI2_EB>;
				#address-cells = <1>;
				#size-cells = <0>;
				status = "disabled";
			};

			spi3: spi@70b00000{
				compatible = "sprd,sc9860-spi", "sprd,roc1-spi";
				reg = <0 0x70b00000 0 0x1000>;
				interrupts = <GIC_SPI 8 IRQ_TYPE_LEVEL_HIGH>;
				clock-names = "enable", "spi", "source";
				clocks = <&apapb_gate CLK_SPI3_EB>;
				#address-cells = <1>;
				#size-cells = <0>;
				status = "disabled";
			};

			sdio3: sdio@71400000 {
				compatible = "sprd,sdhc-r11p1";
				reg = <0 0x71400000 0 0x1000>;
				interrupts = <GIC_SPI 10 IRQ_TYPE_LEVEL_HIGH>;
				status = "disabled";
			};

			sdio0: sdio@71100000 {
				compatible = "sprd,sdhc-r11p1";
				reg = <0 0x71100000  0 0x1000>;
				interrupts = <GIC_SPI 19 IRQ_TYPE_LEVEL_HIGH>;
				status = "disabled";
			};

			sdio1: sdio@71200000 {
				compatible = "sprd,sdhc-r11p1";
				reg = <0 0x71200000 0 0x1000>;
				interrupts = <GIC_SPI 20 IRQ_TYPE_LEVEL_HIGH>;
				status = "disabled";
			};

			sdio2: sdio@71300000 {
				compatible = "sprd,sdhc-r11p1";
				reg = <0 0x71300000 0 0x1000>;
				interrupts = <GIC_SPI 21 IRQ_TYPE_LEVEL_HIGH>;
				status = "disabled";
			};
		};

		agcp {
			compatible = "simple-bus";
			#address-cells = <2>;
			#size-cells = <2>;
			ranges;

			agcp_dma: dma-controller@33580000 {
				compatible = "sprd,roc1-dma";
				reg = <0 0x33580000 0 0x4000>;
				interrupts = <GIC_SPI 180 IRQ_TYPE_LEVEL_HIGH>;
				#dma-cells = <1>;
				#dma-channels = <32>;
				clock-names = "enable", "ashb_eb";
				clocks = <&audcpahb_gate CLK_AUDCP_DMA_AP_EB>,
					<&audcpahb_gate CLK_AUDCP_DMA_AP_ASHB_EB>;
			};
		};

		ap-axi {
			compatible = "simple-bus";
			#address-cells = <2>;
			#size-cells = <2>;
			ranges;

			ipu0: ipu@6fc00000 {
				compatible = "img,ax21xx-nna";
				reg = <0 0x6fc00000 0 0x10000>;
				interrupts = <GIC_SPI 132 IRQ_TYPE_LEVEL_HIGH>;
				interrupt-names = "ai_powervr";
			};
			ipu1: ipu@6fe00000 {
				compatible = "cambricon,1h16-ipu";
				reg = <0 0x6fd08000 0 0x80>,
					<0 0x6fe00000 0 0x1000>,
					<0 0x6fe40000 0 0x1000>,
					<0 0x6ff00000 0 0x1000>;
				reg-names = "ai_iommu", "ipu_regs",
					"ipu_timer", "boot_iram";
				interrupts = <GIC_SPI 133 IRQ_TYPE_LEVEL_HIGH>,
					<GIC_SPI 134 IRQ_TYPE_LEVEL_HIGH>;
				interrupt-names = "ai_cambricon", "ai_mmu";
				iommus = <&iommu_ai>;
			};
		};
	};

	ext_26m: ext-26m {
		compatible = "fixed-clock";
		#clock-cells = <0>;
		clock-frequency = <26000000>;
		clock-output-names = "ext-26m";
	};

	clk_13m: clk-13m {
		compatible = "fixed-factor-clock";
		#clock-cells = <0>;
		clock-mult = <1>;
		clock-div = <2>;
		clocks = <&ext_26m>;
		clock-output-names = "clk-13m";
	};

	clk_6m5: clk-6m5 {
		compatible = "fixed-factor-clock";
		#clock-cells = <0>;
		clock-mult = <1>;
		clock-div = <4>;
		clocks = <&ext_26m>;
		clock-output-names = "clk-6m5";
	};

	clk_4m3: clk-4m3 {
		compatible = "fixed-factor-clock";
		#clock-cells = <0>;
		clock-mult = <1>;
		clock-div = <6>;
		clocks = <&ext_26m>;
		clock-output-names = "clk-4m3";
	};

	clk_2m: clk-2m {
		compatible = "fixed-factor-clock";
		#clock-cells = <0>;
		clock-mult = <1>;
		clock-div = <13>;
		clocks = <&ext_26m>;
		clock-output-names = "clk-2m";
	};

	clk_1m: clk-1m {
		compatible = "fixed-factor-clock";
		#clock-cells = <0>;
		clock-mult = <1>;
		clock-div = <26>;
		clocks = <&ext_26m>;
		clock-output-names = "clk-1m";
	};

	clk_250k: clk-250k {
		compatible = "fixed-factor-clock";
		#clock-cells = <0>;
		clock-mult = <1>;
		clock-div = <104>;
		clocks = <&ext_26m>;
		clock-output-names = "clk-250k";
	};

	ext_32k: ext_32k {
		compatible = "fixed-clock";
		#clock-cells = <0>;
		clock-frequency = <32768>;
		clock-output-names = "ext-32k";
	};

	ext_rco_100m: ext-rco-100m {
		compatible = "fixed-clock";
		#clock-cells = <0>;
		clock-frequency = <100000000>;
		clock-output-names = "ext-rco-100m";
	};

	rco_25m: rco-25m {
		compatible = "fixed-factor-clock";
		#clock-cells = <0>;
		clock-mult = <1>;
		clock-div = <4>;
		clocks = <&ext_rco_100m>;
		clock-output-names = "rco-25m";
	};

	rco_4m: rco-4m {
		compatible = "fixed-factor-clock";
		#clock-cells = <0>;
		clock-mult = <1>;
		clock-div = <25>;
		clocks = <&ext_rco_100m>;
		clock-output-names = "rco-4m";
	};

	rco_2m: rco-2m {
		compatible = "fixed-factor-clock";
		#clock-cells = <0>;
		clock-mult = <1>;
		clock-div = <50>;
		clocks = <&ext_rco_100m>;
		clock-output-names = "rco-2m";
	};
};

